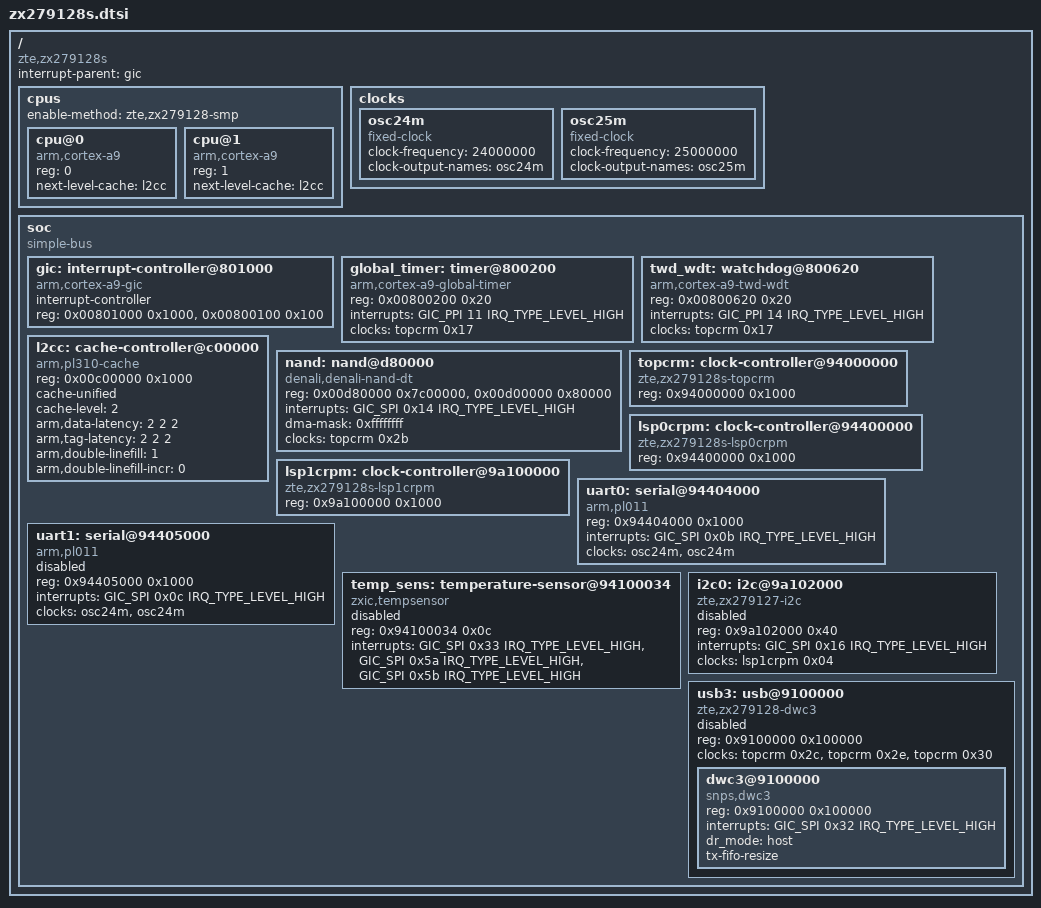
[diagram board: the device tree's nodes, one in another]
// SPDX-License-Identifier: GPL-2.0
/*
 * Device tree for ZTE ZXIC ZX279128S SoC
 *
 * Cortex-A9 dual-core @ 1 GHz, 256 MiB DDR @ 0x40000000
 *
 * Reverse-engineered from extracted DTB of stock ZTE H3600 firmware
 * (V9.0.20 patch 72) + decompiled vmlinux + .ko symbols.
 *
 * Kernel virtual addresses for static iomap (per stock kernel earlyprintk):
 *   0x94000000 → 0xf0400000  (TOPCRM)
 *   0x94100000 → 0xf0500000  (temp sensor)
 *   0x94400000 → 0xf0700000  (LSP0CRPM)
 *   0x9a100000 → 0xf0800000  (LSP1CRPM/MDIO/I2C)
 *   0x00d00000 → 0xf0900000  (NAND reg)
 *   0x92000000 → 0xf4000000  (PON)
 *   0x09100000 → 0xf0b00000  (USB3 dwc3)
 */

#include <dt-bindings/interrupt-controller/arm-gic.h>

/ {
	#address-cells = <1>;
	#size-cells = <1>;
	compatible = "zte,zx279128s";
	interrupt-parent = <&gic>;

	cpus {
		#address-cells = <1>;
		#size-cells = <0>;
		enable-method = "zte,zx279128-smp";

		cpu@0 {
			compatible = "arm,cortex-a9";
			device_type = "cpu";
			reg = <0>;
			next-level-cache = <&l2cc>;
		};

		cpu@1 {
			compatible = "arm,cortex-a9";
			device_type = "cpu";
			reg = <1>;
			next-level-cache = <&l2cc>;
		};
	};

	clocks {
		osc24m: osc24m {
			compatible = "fixed-clock";
			#clock-cells = <0>;
			clock-frequency = <24000000>;
			clock-output-names = "osc24m";
		};

		osc25m: osc25m {
			compatible = "fixed-clock";
			#clock-cells = <0>;
			clock-frequency = <25000000>;
			clock-output-names = "osc25m";
		};
	};

	soc {
		#address-cells = <1>;
		#size-cells = <1>;
		compatible = "simple-bus";
		ranges;

		/* ARM Cortex-A9 standard peripherals — same offsets as ZX296702 */
		gic: interrupt-controller@801000 {
			compatible = "arm,cortex-a9-gic";
			#interrupt-cells = <3>;
			interrupt-controller;
			reg = <0x00801000 0x1000>,
			      <0x00800100 0x100>;
		};

		global_timer: timer@800200 {
			compatible = "arm,cortex-a9-global-timer";
			reg = <0x00800200 0x20>;
			interrupts = <GIC_PPI 11 IRQ_TYPE_LEVEL_HIGH>;
			clocks = <&topcrm 0x17>;
		};

		twd_wdt: watchdog@800620 {
			compatible = "arm,cortex-a9-twd-wdt";
			reg = <0x00800620 0x20>;
			interrupts = <GIC_PPI 14 IRQ_TYPE_LEVEL_HIGH>;
			clocks = <&topcrm 0x17>;
		};

		l2cc: cache-controller@c00000 {
			compatible = "arm,pl310-cache";
			reg = <0x00c00000 0x1000>;
			cache-unified;
			cache-level = <2>;
			arm,data-latency = <2 2 2>;
			arm,tag-latency = <2 2 2>;
			arm,double-linefill = <1>;
			arm,double-linefill-incr = <0>;
		};

		/* SoC-specific blocks */
		nand: nand@d80000 {
			compatible = "denali,denali-nand-dt";
			#address-cells = <1>;
			#size-cells = <1>;
			reg = <0x00d80000 0x7c00000>,
			      <0x00d00000 0x80000>;
			reg-names = "nand_data", "denali_reg";
			interrupts = <GIC_SPI 0x14 IRQ_TYPE_LEVEL_HIGH>;
			dma-mask = <0xffffffff>;
			clocks = <&topcrm 0x2b>;
			status = "okay";
		};

		/*
		 * Clock controllers — drivers in drivers/clk/zte/
		 * Compatible names match the stock ZTE driver.
		 */
		topcrm: clock-controller@94000000 {
			compatible = "zte,zx279128s-topcrm", "zte,zx279127-topcrm",
				     "syscon";
			reg = <0x94000000 0x1000>;
			#clock-cells = <1>;
		};

		lsp0crpm: clock-controller@94400000 {
			compatible = "zte,zx279128s-lsp0crpm",
				     "zte,zx279127-lsp0crpm";
			reg = <0x94400000 0x1000>;
			#clock-cells = <1>;
		};

		lsp1crpm: clock-controller@9a100000 {
			compatible = "zte,zx279128s-lsp1crpm",
				     "zte,zx279127-lsp1crpm";
			reg = <0x9a100000 0x1000>;
			#clock-cells = <1>;
		};

		/*
		 * UART — stock firmware advertises "zte,ZX279127-uart" but
		 * runs amba-pl011 driver per bootlog ("Serial: AMBA PL011").
		 * Mainline arm,pl011 should work directly.
		 */
		uart0: serial@94404000 {
			compatible = "arm,pl011", "arm,primecell";
			reg = <0x94404000 0x1000>;
			interrupts = <GIC_SPI 0x0b IRQ_TYPE_LEVEL_HIGH>;
			clocks = <&osc24m>, <&osc24m>;
			clock-names = "uartclk", "apb_pclk";
			status = "okay";
		};

		uart1: serial@94405000 {
			compatible = "arm,pl011", "arm,primecell";
			reg = <0x94405000 0x1000>;
			interrupts = <GIC_SPI 0x0c IRQ_TYPE_LEVEL_HIGH>;
			clocks = <&osc24m>, <&osc24m>;
			clock-names = "uartclk", "apb_pclk";
			status = "disabled";
		};

		/* I2C / SPI / temp / etc. — disabled by default for first boot */
		temp_sens: temperature-sensor@94100034 {
			compatible = "zxic,tempsensor";
			reg = <0x94100034 0x0c>;
			interrupts = <GIC_SPI 0x33 IRQ_TYPE_LEVEL_HIGH>,
				     <GIC_SPI 0x5a IRQ_TYPE_LEVEL_HIGH>,
				     <GIC_SPI 0x5b IRQ_TYPE_LEVEL_HIGH>;
			status = "disabled";
		};

		i2c0: i2c@9a102000 {
			compatible = "zte,zx279127-i2c";
			reg = <0x9a102000 0x40>;
			interrupts = <GIC_SPI 0x16 IRQ_TYPE_LEVEL_HIGH>;
			clocks = <&lsp1crpm 0x04>;
			status = "disabled";
		};

		usb3: usb@9100000 {
			compatible = "zte,zx279128-dwc3";
			reg = <0x9100000 0x100000>;
			clocks = <&topcrm 0x2c>, <&topcrm 0x2e>, <&topcrm 0x30>;
			clock-names = "usb_bus_clk", "usb_ref_clk0", "usb_ref_clk1";
			#address-cells = <1>;
			#size-cells = <1>;
			ranges;
			status = "disabled";

			dwc3@9100000 {
				compatible = "snps,dwc3";
				reg = <0x9100000 0x100000>;
				interrupts = <GIC_SPI 0x32 IRQ_TYPE_LEVEL_HIGH>;
				dr_mode = "host";
				tx-fifo-resize;
			};
		};
	};
};
